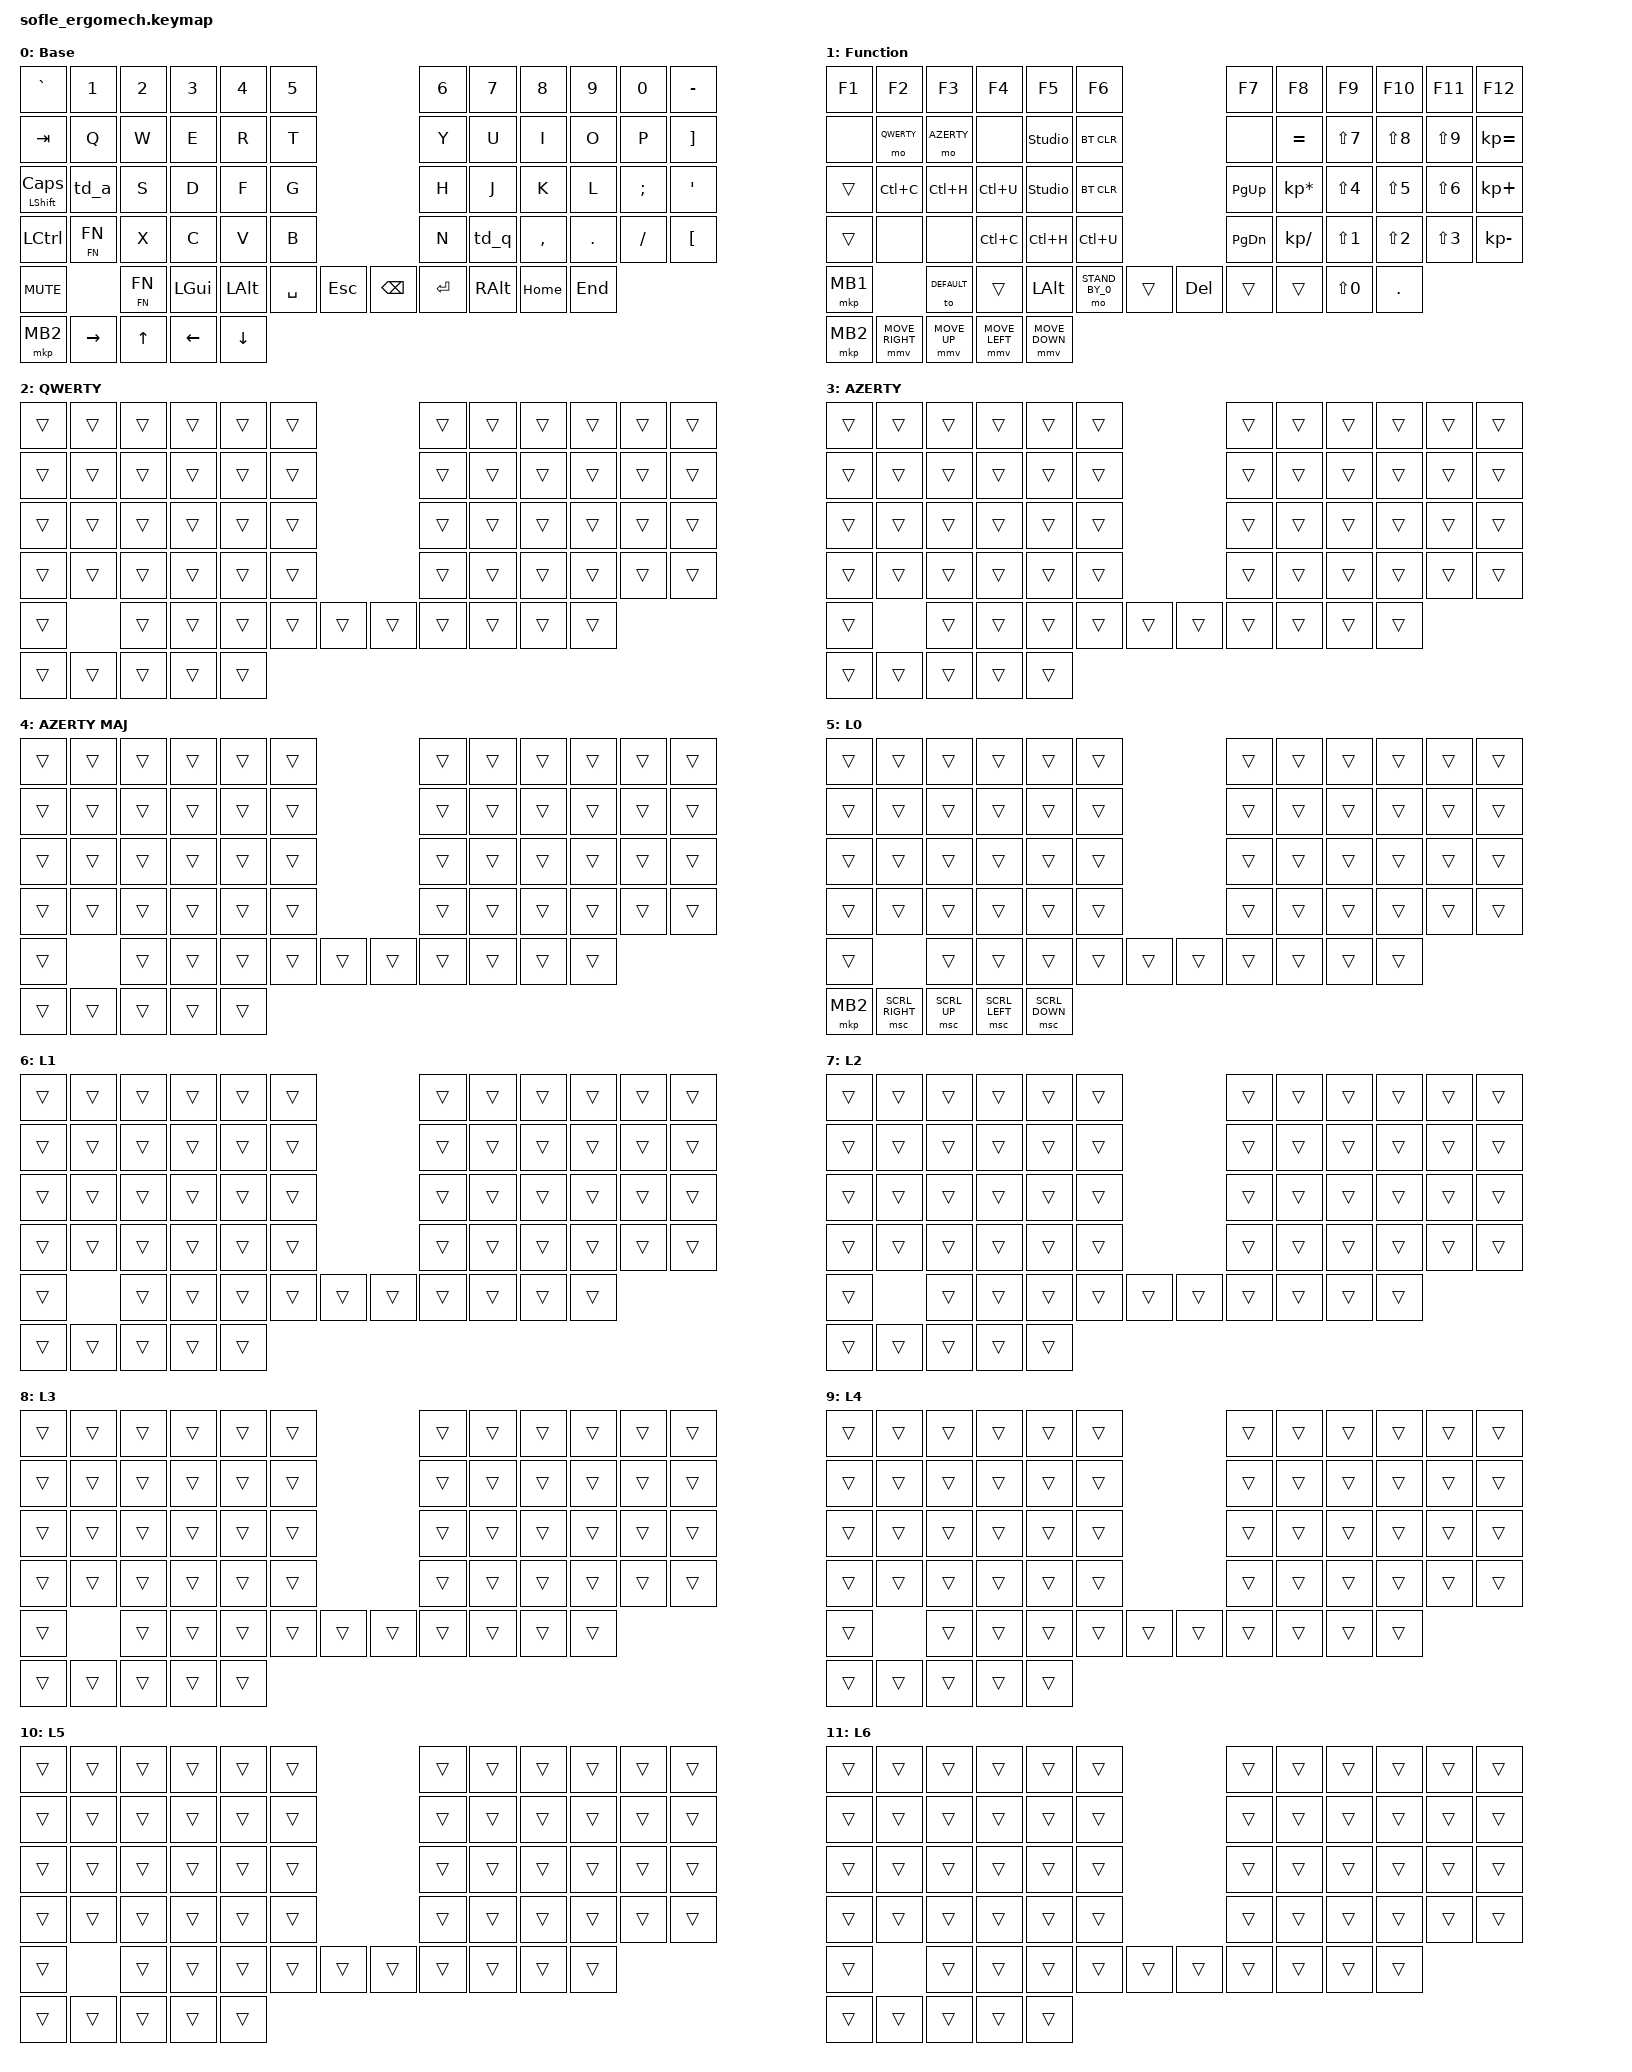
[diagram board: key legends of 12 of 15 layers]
/*
 * Copyright (c) 2020 The ZMK Contributors
 *
 * SPDX-License-Identifier: MIT
 */

#define ZMK_POINTING_DEFAULT_SCRL_VAL 300

#include <behaviors.dtsi>
#include <behaviors/mouse_move.dtsi>
#include <dt-bindings/zmk/keys.h>
#include <dt-bindings/zmk/pointing.h>

#include <dt-bindings/zmk/backlight.h>
#include <dt-bindings/zmk/behaviors.h>
#include <dt-bindings/zmk/bt.h>
#include <dt-bindings/zmk/ext_power.h>
#include <dt-bindings/zmk/hid_usage.h>
#include <dt-bindings/zmk/hid_usage_pages.h>
#include <dt-bindings/zmk/input_transform.h>
#include <dt-bindings/zmk/keys.h>
#include <dt-bindings/zmk/matrix_transform.h>
#include <dt-bindings/zmk/modifiers.h>
#include <dt-bindings/zmk/outputs.h>
#include <dt-bindings/zmk/pointing.h>
#include <dt-bindings/zmk/reset.h>
#include <dt-bindings/zmk/rgb.h>


#define DEFAULT     0
#define FN          1
#define QWERTY      2
#define AZERTY      3
#define AZERTY_MAJ  4

#define STAND_BY_0  5
#define STAND_BY_1  6
#define STAND_BY_2  7
#define STAND_BY_3  8
#define STAND_BY_4  9
#define STAND_BY_5  10
#define STAND_BY_6  11
#define STAND_BY_7  12
#define STAND_BY_8  13
#define STAND_BY_9  14

/ {
	behaviors {
		scrollup: scrollup {
			compatible = "zmk,behavior-macro";
            #binding-cells = <0>;
            bindings = <&msc SCRL_UP>, <&msc SCRL_UP>, <&msc SCRL_UP>, <&msc SCRL_UP>, <&msc SCRL_UP>, <&msc SCRL_UP>;
		};
		
		scrolldown: scrolldown {
			compatible = "zmk,behavior-macro";
            #binding-cells = <0>;
            bindings = <&msc SCRL_DOWN>, <&msc SCRL_DOWN>, <&msc SCRL_DOWN>, <&msc SCRL_DOWN>, <&msc SCRL_DOWN>, <&msc SCRL_DOWN>;
		};
		
		mousescroll: mousescroll {
            compatible = "zmk,behavior-sensor-rotate";
            #sensor-binding-cells = <0>;
            bindings = <&scrollup>, <&scrolldown>;
			tap-ms = <50>;
		};
		
		shift: hold_tap_shift {
			compatible = "zmk,behavior-hold-tap";
			#binding-cells = <2>;
			flavor = "hold-preferred";
			tapping-term-ms = <200>;
			bindings = <&kp>, <&kp>;
		};
		
		ht_l: hold_tap_layer {
			compatible = "zmk,behavior-hold-tap";
			#binding-cells = <2>;
			flavor = "hold-preferred";
			tapping-term-ms = <200>;
			bindings = <&mo>, <&to>;
		};
		
		td_q: td_q {
			compatible = "zmk,behavior-tap-dance";
			#binding-cells = <0>;
			tapping-term-ms = <200>;
			bindings = <&kp M>, <&kp BSLH>;
		};
		
		td_a: td_a {
			compatible = "zmk,behavior-tap-dance";
			#binding-cells = <0>;
			tapping-term-ms = <200>;
			bindings = <&kp A>, <&kp Z>;
		};
		
		// JOYSTICK
		kp_right: kp_right {
			compatible = "zmk,behavior-mod-morph";
            #binding-cells = <0>;
            bindings = <&kp RIGHT>, <&kp END>;
            mods = <MOD_LALT>;
		};
		
		kp_up: kp_up {
			compatible = "zmk,behavior-mod-morph";
            #binding-cells = <0>;
            bindings = <&kp UP>, <&kp PAGE_UP>;
            mods = <MOD_LALT>;
		};
		
		kp_left: kp_left {
			compatible = "zmk,behavior-mod-morph";
            #binding-cells = <0>;
            bindings = <&kp LEFT>, <&kp HOME>;
            mods = <MOD_LALT>;
		};
		
		kp_down: kp_down {
			compatible = "zmk,behavior-mod-morph";
            #binding-cells = <0>;
            bindings = <&kp DOWN>, <&kp PAGE_DOWN>;
            mods = <MOD_LALT>;
		};
	};
	
    keymap {
		compatible = "zmk,keymap";
		default_layer {
			label = "Base";
// ── DEFAULT ─────────────────────────────────────────────────────────────────────────────────────────────────────────────────────────────────────────────────────────────────────────────────────────────────────────────────────────────────────────
			bindings = <
// ╭────────────────┬────────────────┬────────────────┬────────────────┬────────────────┬────────────────╮                                      ╭────────────────┬────────────────┬────────────────┬────────────────┬────────────────┬────────────────╮
// │ $              │ "              │ «              │ »              │ (              │ )              │                                      │ @              │ +              │ -              │ /              │ *              │ =              │
     &kp GRAVE        &kp N1           &kp N2           &kp N3           &kp N4           &kp N5                                                  &kp N6           &kp N7           &kp N8            &kp N9          &kp N0           &kp MINUS
// ├────────────────┼────────────────┼────────────────┼────────────────┼────────────────┼────────────────┤                                      ├────────────────┼────────────────┼────────────────┼────────────────┼────────────────┼────────────────┤
// │ TAB            │ b              │ é              │ p              │ o              │ è              │                                      │ ^              │ v              │ d              │ l              │ j              │ w              │
     &kp TAB          &kp Q            &kp W            &kp E            &kp R            &kp T                                                   &kp Y            &kp U            &kp I            &kp O            &kp P            &kp RBKT
// ├────────────────┼────────────────┼────────────────┼────────────────┼────────────────┼────────────────┤                                      ├────────────────┼────────────────┼────────────────┼────────────────┼────────────────┼────────────────┤
// │ MAJ            │ a              │ u              │ i              │ e              │ ,              │                                      │ c              │ t              │ s              │ r              │ n              │ m              │
    &shift LSHFT CLCK &td_a            &kp S            &kp D            &kp F            &kp G                                                   &kp H            &kp J            &kp K            &kp L            &kp SEMI         &kp SQT
// ├────────────────┼────────────────┼────────────────┼────────────────┼────────────────┼────────────────┤                                      ├────────────────┼────────────────┼────────────────┼────────────────┼────────────────┼────────────────┤
// │ CTRL           │ à              │ y              │ x              │ .              │ k              │                                      │ '              │ q/ç            │ g              │ h              │ f              │ z              │
     &kp LCTRL        &ht_l FN FN        &kp X            &kp C            &kp V            &kp B                                                   &kp N            &td_q            &kp COMMA        &kp DOT          &kp FSLH         &kp LBKT
// ╰────────────────┴────────────────┼────────────────┼────────────────┼────────────────┼────────────────┼────────────────╮    ╭────────────────┼────────────────┼────────────────┼────────────────┼────────────────┼────────────────┼────────────────╯
//                                   │ <FN>           │ WIN            │ ALT            │ SPACE          │ ESC            │    │ BKSPC          │ ENTER          │ ALTGR          │ HOME           │ END            │
     &kp C_MUTE                        &ht_l FN FN      &kp LGUI         &kp LALT         &kp SPACE        &kp ESC               &kp BSPC         &kp ENTER        &kp RALT         &kp HOME         &kp END
//                                   ╰────────────────┴────────────────┴────────────────┴────────────────┴────────────────╯    ╰────────────────┴────────────────┴────────────────┴────────────────┴────────────────╯
&mkp MB2 &kp RIGHT &kp UP &kp LEFT &kp DOWN
			>;
			sensor-bindings = <&mousescroll &inc_dec_kp PG_UP PG_DN>;
		};
		
		fn_layer {
			label = "Function";
// ── FN ──────────────────────────────────────────────────────────────────────────────────────────────────────────────────────────────────────────────────────────────────────────────────────────────────────────────────────────────────────────────
			bindings = <
// ╭────────────────┬────────────────┬────────────────┬────────────────┬────────────────┬────────────────╮                                      ╭────────────────┬────────────────┬────────────────┬────────────────┬────────────────┬────────────────╮
// │ F1             │ F2             │ F3             │ F4             │ F5             │ F6             │                                      │ F7             │ F8             │ F9             │ F10            │ F11            │ F12            │
     &kp F1           &kp F2           &kp F3           &kp F4           &kp F5           &kp F6                                                  &kp F7           &kp F8           &kp F9           &kp F10          &kp F11          &kp F12
// ├────────────────┼────────────────┼────────────────┼────────────────┼────────────────┼────────────────┤                                      ├────────────────┼────────────────┼────────────────┼────────────────┼────────────────┼────────────────┤
// │ studio         │ QWERTY         │ AZERTY         │                │                │                │                                      │                │ %              │ 7              │ 8              │ 9              │ =              │
     &none            &mo QWERTY       &mo AZERTY       &none            &studio_unlock   &bt BT_CLR                                              &none            &kp EQUAL        &kp LS(N7)       &kp LS(N8)       &kp LS(N9)       &kp KP_EQUAL
// ├────────────────┼────────────────┼────────────────┼────────────────┼────────────────┼────────────────┤                                      ├────────────────┼────────────────┼────────────────┼────────────────┼────────────────┼────────────────┤
// │ studio         │ CUT            │ COPY           │ PASTE          │                │                │                                      │ PAGE_UP        │ *              │ 4              │ 5              │ 6              │ +              │
     &trans           &kp LC(C)        &kp LC(H)        &kp LC(U)        &studio_unlock   &bt BT_CLR                                              &kp PAGE_UP      &kp KP_MULTIPLY  &kp LS(N4)       &kp LS(N5)       &kp LS(N6)       &kp KP_PLUS
// ├────────────────┼────────────────┼────────────────┼────────────────┼────────────────┼────────────────┤                                      ├────────────────┼────────────────┼────────────────┼────────────────┼────────────────┼────────────────┤
// │ BLUETOOTH      │                │                │ CUT            │ COPY           │ PASTE          │                                      │ PAGE_DOWN      │ /              │ 1              │ 2              │ 3              │ -              │
     &trans           &none            &none            &kp LC(C)        &kp LC(H)        &kp LC(U)                                               &kp PAGE_DOWN    &kp KP_SLASH     &kp LS(N1)       &kp LS(N2)       &kp LS(N3)       &kp KP_MINUS
// ╰────────────────┴────────────────┼────────────────┼────────────────┼────────────────┼────────────────┼────────────────╮    ╭────────────────┼────────────────┼────────────────┼────────────────┼────────────────┼────────────────┼────────────────╯
//                                   │ <FN>           │ WIN            │ ALT            │ STAND_BY_1     │ ESC            │    │ BKSPC          │ ENTER          │ ALTGR          │ 0              │ .              │
     &mkp MB1                          &to DEFAULT      &trans           &kp LALT         &mo STAND_BY_0   &trans                &kp DELETE       &trans           &trans           &kp LS(N0)       &kp DOT
//                                   ╰────────────────┴────────────────┴────────────────┴────────────────┴────────────────╯    ╰────────────────┴────────────────┴────────────────┴────────────────┴────────────────╯
&mkp MB2 &mmv MOVE_RIGHT &mmv MOVE_UP &mmv MOVE_LEFT &mmv MOVE_DOWN
			>;
			sensor-bindings = <&inc_dec_kp C_VOL_UP C_VOL_DN &inc_dec_kp PG_UP PG_DN>;
		};
		
		qwerty_layer {
			label = "QWERTY";
// ── QWERTY ──────────────────────────────────────────────────────────────────────────────────────────────────────────────────────────────────────────────────────────────────────────────────────────────────────────────────────────────────────────
			bindings = <
// ╭────────────────┬────────────────┬────────────────┬────────────────┬────────────────┬────────────────╮                                      ╭────────────────┬────────────────┬────────────────┬────────────────┬────────────────┬────────────────╮
// │                │                │                │                │                │                │                                      │                │                │                │                │                │                │
     &trans           &trans           &trans           &trans           &trans           &trans                                                  &trans           &trans           &trans           &trans           &trans           &trans
// ├────────────────┼────────────────┼────────────────┼────────────────┼────────────────┼────────────────┤                                      ├────────────────┼────────────────┼────────────────┼────────────────┼────────────────┼────────────────┤
// │                │                │                │                │                │                │                                      │                │                │                │                │                │                │
     &trans           &trans           &trans           &trans           &trans           &trans                                                  &trans           &trans           &trans           &trans           &trans           &trans
// ├────────────────┼────────────────┼────────────────┼────────────────┼────────────────┼────────────────┤                                      ├────────────────┼────────────────┼────────────────┼────────────────┼────────────────┼────────────────┤
// │                │                │                │                │                │                │                                      │                │                │                │                │                │                │
     &trans           &trans           &trans           &trans           &trans           &trans                                                  &trans           &trans           &trans           &trans           &trans           &trans
// ├────────────────┼────────────────┼────────────────┼────────────────┼────────────────┼────────────────┤                                      ├────────────────┼────────────────┼────────────────┼────────────────┼────────────────┼────────────────┤
// │                │                │                │                │                │                │                                      │                │                │                │                │                │                │
     &trans           &trans           &trans           &trans           &trans           &trans                                                  &trans           &trans           &trans           &trans           &trans           &trans
// ╰────────────────┴────────────────┼────────────────┼────────────────┼────────────────┼────────────────┼────────────────╮    ╭────────────────┼────────────────┼────────────────┼────────────────┼────────────────┼────────────────┼────────────────╯
//                                   │                │                │                │                │                │    │                │                │                │                │                │
     &trans                            &trans           &trans           &trans           &trans           &trans                &trans           &trans           &trans           &trans           &trans
//                                   ╰────────────────┴────────────────┴────────────────┴────────────────┴────────────────╯    ╰────────────────┴────────────────┴────────────────┴────────────────┴────────────────╯
&trans &trans &trans &trans &trans
			>;
			sensor-bindings = <&inc_dec_kp C_VOL_UP C_VOL_DN &inc_dec_kp PG_UP PG_DN>;
		};
		
		azerty_layer {
			label = "AZERTY";
// ── AZERTY ──────────────────────────────────────────────────────────────────────────────────────────────────────────────────────────────────────────────────────────────────────────────────────────────────────────────────────────────────────────
			bindings = <
// ╭────────────────┬────────────────┬────────────────┬────────────────┬────────────────┬────────────────╮                                      ╭────────────────┬────────────────┬────────────────┬────────────────┬────────────────┬────────────────╮
// │                │                │                │                │                │                │                                      │                │                │                │                │                │                │
     &trans           &trans           &trans           &trans           &trans           &trans                                                  &trans           &trans           &trans           &trans           &trans           &trans
// ├────────────────┼────────────────┼────────────────┼────────────────┼────────────────┼────────────────┤                                      ├────────────────┼────────────────┼────────────────┼────────────────┼────────────────┼────────────────┤
// │                │                │                │                │                │                │                                      │                │                │                │                │                │                │
     &trans           &trans           &trans           &trans           &trans           &trans                                                  &trans           &trans           &trans           &trans           &trans           &trans
// ├────────────────┼────────────────┼────────────────┼────────────────┼────────────────┼────────────────┤                                      ├────────────────┼────────────────┼────────────────┼────────────────┼────────────────┼────────────────┤
// │                │                │                │                │                │                │                                      │                │                │                │                │                │                │
     &trans           &trans           &trans           &trans           &trans           &trans                                                  &trans           &trans           &trans           &trans           &trans           &trans
// ├────────────────┼────────────────┼────────────────┼────────────────┼────────────────┼────────────────┤                                      ├────────────────┼────────────────┼────────────────┼────────────────┼────────────────┼────────────────┤
// │                │                │                │                │                │                │                                      │                │                │                │                │                │                │
     &trans           &trans           &trans           &trans           &trans           &trans                                                  &trans           &trans           &trans           &trans           &trans           &trans
// ╰────────────────┴────────────────┼────────────────┼────────────────┼────────────────┼────────────────┼────────────────╮    ╭────────────────┼────────────────┼────────────────┼────────────────┼────────────────┼────────────────┼────────────────╯
//                                   │                │                │                │                │                │    │                │                │                │                │                │
     &trans                            &trans           &trans           &trans           &trans           &trans                &trans           &trans           &trans           &trans           &trans
//                                   ╰────────────────┴────────────────┴────────────────┴────────────────┴────────────────╯    ╰────────────────┴────────────────┴────────────────┴────────────────┴────────────────╯
&trans &trans &trans &trans &trans
			>;
			sensor-bindings = <&inc_dec_kp C_VOL_UP C_VOL_DN &inc_dec_kp PG_UP PG_DN>;
		};
		
		azertymaj_layer {
			label = "AZERTY MAJ";
// ── AZERTY ──────────────────────────────────────────────────────────────────────────────────────────────────────────────────────────────────────────────────────────────────────────────────────────────────────────────────────────────────────────
			bindings = <
// ╭────────────────┬────────────────┬────────────────┬────────────────┬────────────────┬────────────────╮                                      ╭────────────────┬────────────────┬────────────────┬────────────────┬────────────────┬────────────────╮
// │                │                │                │                │                │                │                                      │                │                │                │                │                │                │
     &trans           &trans           &trans           &trans           &trans           &trans                                                  &trans           &trans           &trans           &trans           &trans           &trans
// ├────────────────┼────────────────┼────────────────┼────────────────┼────────────────┼────────────────┤                                      ├────────────────┼────────────────┼────────────────┼────────────────┼────────────────┼────────────────┤
// │                │                │                │                │                │                │                                      │                │                │                │                │                │                │
     &trans           &trans           &trans           &trans           &trans           &trans                                                  &trans           &trans           &trans           &trans           &trans           &trans
// ├────────────────┼────────────────┼────────────────┼────────────────┼────────────────┼────────────────┤                                      ├────────────────┼────────────────┼────────────────┼────────────────┼────────────────┼────────────────┤
// │                │                │                │                │                │                │                                      │                │                │                │                │                │                │
     &trans           &trans           &trans           &trans           &trans           &trans                                                  &trans           &trans           &trans           &trans           &trans           &trans
// ├────────────────┼────────────────┼────────────────┼────────────────┼────────────────┼────────────────┤                                      ├────────────────┼────────────────┼────────────────┼────────────────┼────────────────┼────────────────┤
// │                │                │                │                │                │                │                                      │                │                │                │                │                │                │
     &trans           &trans           &trans           &trans           &trans           &trans                                                  &trans           &trans           &trans           &trans           &trans           &trans
// ╰────────────────┴────────────────┼────────────────┼────────────────┼────────────────┼────────────────┼────────────────╮    ╭────────────────┼────────────────┼────────────────┼────────────────┼────────────────┼────────────────┼────────────────╯
//                                   │                │                │                │                │                │    │                │                │                │                │                │
     &trans                            &trans           &trans           &trans           &trans           &trans                &trans           &trans           &trans           &trans           &trans
//                                   ╰────────────────┴────────────────┴────────────────┴────────────────┴────────────────╯    ╰────────────────┴────────────────┴────────────────┴────────────────┴────────────────╯
&trans &trans &trans &trans &trans
			>;
			sensor-bindings = <&inc_dec_kp C_VOL_UP C_VOL_DN &inc_dec_kp PG_UP PG_DN>;
		};
		
		standby0_layer {
			label = "L0";
// ── AZERTY ──────────────────────────────────────────────────────────────────────────────────────────────────────────────────────────────────────────────────────────────────────────────────────────────────────────────────────────────────────────
			bindings = <
// ╭────────────────┬────────────────┬────────────────┬────────────────┬────────────────┬────────────────╮                                      ╭────────────────┬────────────────┬────────────────┬────────────────┬────────────────┬────────────────╮
// │                │                │                │                │                │                │                                      │                │                │                │                │                │                │
     &trans           &trans           &trans           &trans           &trans           &trans                                                  &trans           &trans           &trans           &trans           &trans           &trans
// ├────────────────┼────────────────┼────────────────┼────────────────┼────────────────┼────────────────┤                                      ├────────────────┼────────────────┼────────────────┼────────────────┼────────────────┼────────────────┤
// │                │                │                │                │                │                │                                      │                │                │                │                │                │                │
     &trans           &trans           &trans           &trans           &trans           &trans                                                  &trans           &trans           &trans           &trans           &trans           &trans
// ├────────────────┼────────────────┼────────────────┼────────────────┼────────────────┼────────────────┤                                      ├────────────────┼────────────────┼────────────────┼────────────────┼────────────────┼────────────────┤
// │                │                │                │                │                │                │                                      │                │                │                │                │                │                │
     &trans           &trans           &trans           &trans           &trans           &trans                                                  &trans           &trans           &trans           &trans           &trans           &trans
// ├────────────────┼────────────────┼────────────────┼────────────────┼────────────────┼────────────────┤                                      ├────────────────┼────────────────┼────────────────┼────────────────┼────────────────┼────────────────┤
// │                │                │                │                │                │                │                                      │                │                │                │                │                │                │
     &trans           &trans           &trans           &trans           &trans           &trans                                                  &trans           &trans           &trans           &trans           &trans           &trans
// ╰────────────────┴────────────────┼────────────────┼────────────────┼────────────────┼────────────────┼────────────────╮    ╭────────────────┼────────────────┼────────────────┼────────────────┼────────────────┼────────────────┼────────────────╯
//                                   │                │                │                │                │                │    │                │                │                │                │                │
     &trans                            &trans           &trans           &trans           &trans           &trans                &trans           &trans           &trans           &trans           &trans
//                                   ╰────────────────┴────────────────┴────────────────┴────────────────┴────────────────╯    ╰────────────────┴────────────────┴────────────────┴────────────────┴────────────────╯
&mkp MB2 &msc SCRL_RIGHT &msc SCRL_UP &msc SCRL_LEFT &msc SCRL_DOWN
			>;
			sensor-bindings = <&inc_dec_kp C_VOL_UP C_VOL_DN &inc_dec_kp PG_UP PG_DN>;
		};
		
		standby1_layer {
			label = "L1";
// ── AZERTY ──────────────────────────────────────────────────────────────────────────────────────────────────────────────────────────────────────────────────────────────────────────────────────────────────────────────────────────────────────────
			bindings = <
// ╭────────────────┬────────────────┬────────────────┬────────────────┬────────────────┬────────────────╮                                      ╭────────────────┬────────────────┬────────────────┬────────────────┬────────────────┬────────────────╮
// │                │                │                │                │                │                │                                      │                │                │                │                │                │                │
     &trans           &trans           &trans           &trans           &trans           &trans                                                  &trans           &trans           &trans           &trans           &trans           &trans
// ├────────────────┼────────────────┼────────────────┼────────────────┼────────────────┼────────────────┤                                      ├────────────────┼────────────────┼────────────────┼────────────────┼────────────────┼────────────────┤
// │                │                │                │                │                │                │                                      │                │                │                │                │                │                │
     &trans           &trans           &trans           &trans           &trans           &trans                                                  &trans           &trans           &trans           &trans           &trans           &trans
// ├────────────────┼────────────────┼────────────────┼────────────────┼────────────────┼────────────────┤                                      ├────────────────┼────────────────┼────────────────┼────────────────┼────────────────┼────────────────┤
// │                │                │                │                │                │                │                                      │                │                │                │                │                │                │
     &trans           &trans           &trans           &trans           &trans           &trans                                                  &trans           &trans           &trans           &trans           &trans           &trans
// ├────────────────┼────────────────┼────────────────┼────────────────┼────────────────┼────────────────┤                                      ├────────────────┼────────────────┼────────────────┼────────────────┼────────────────┼────────────────┤
// │                │                │                │                │                │                │                                      │                │                │                │                │                │                │
     &trans           &trans           &trans           &trans           &trans           &trans                                                  &trans           &trans           &trans           &trans           &trans           &trans
// ╰────────────────┴────────────────┼────────────────┼────────────────┼────────────────┼────────────────┼────────────────╮    ╭────────────────┼────────────────┼────────────────┼────────────────┼────────────────┼────────────────┼────────────────╯
//                                   │                │                │                │                │                │    │                │                │                │                │                │
     &trans                            &trans           &trans           &trans           &trans           &trans                &trans           &trans           &trans           &trans           &trans
//                                   ╰────────────────┴────────────────┴────────────────┴────────────────┴────────────────╯    ╰────────────────┴────────────────┴────────────────┴────────────────┴────────────────╯
&trans &trans &trans &trans &trans
			>;
			sensor-bindings = <&inc_dec_kp C_VOL_UP C_VOL_DN &inc_dec_kp PG_UP PG_DN>;
		};
		
		standby2_layer {
			label = "L2";
// ── AZERTY ──────────────────────────────────────────────────────────────────────────────────────────────────────────────────────────────────────────────────────────────────────────────────────────────────────────────────────────────────────────
			bindings = <
// ╭────────────────┬────────────────┬────────────────┬────────────────┬────────────────┬────────────────╮                                      ╭────────────────┬────────────────┬────────────────┬────────────────┬────────────────┬────────────────╮
// │                │                │                │                │                │                │                                      │                │                │                │                │                │                │
     &trans           &trans           &trans           &trans           &trans           &trans                                                  &trans           &trans           &trans           &trans           &trans           &trans
// ├────────────────┼────────────────┼────────────────┼────────────────┼────────────────┼────────────────┤                                      ├────────────────┼────────────────┼────────────────┼────────────────┼────────────────┼────────────────┤
// │                │                │                │                │                │                │                                      │                │                │                │                │                │                │
     &trans           &trans           &trans           &trans           &trans           &trans                                                  &trans           &trans           &trans           &trans           &trans           &trans
// ├────────────────┼────────────────┼────────────────┼────────────────┼────────────────┼────────────────┤                                      ├────────────────┼────────────────┼────────────────┼────────────────┼────────────────┼────────────────┤
// │                │                │                │                │                │                │                                      │                │                │                │                │                │                │
     &trans           &trans           &trans           &trans           &trans           &trans                                                  &trans           &trans           &trans           &trans           &trans           &trans
// ├────────────────┼────────────────┼────────────────┼────────────────┼────────────────┼────────────────┤                                      ├────────────────┼────────────────┼────────────────┼────────────────┼────────────────┼────────────────┤
// │                │                │                │                │                │                │                                      │                │                │                │                │                │                │
     &trans           &trans           &trans           &trans           &trans           &trans                                                  &trans           &trans           &trans           &trans           &trans           &trans
// ╰────────────────┴────────────────┼────────────────┼────────────────┼────────────────┼────────────────┼────────────────╮    ╭────────────────┼────────────────┼────────────────┼────────────────┼────────────────┼────────────────┼────────────────╯
//                                   │                │                │                │                │                │    │                │                │                │                │                │
     &trans                            &trans           &trans           &trans           &trans           &trans                &trans           &trans           &trans           &trans           &trans
//                                   ╰────────────────┴────────────────┴────────────────┴────────────────┴────────────────╯    ╰────────────────┴────────────────┴────────────────┴────────────────┴────────────────╯
&trans &trans &trans &trans &trans
			>;
			sensor-bindings = <&inc_dec_kp C_VOL_UP C_VOL_DN &inc_dec_kp PG_UP PG_DN>;
		};
		
		standby3_layer {
			label = "L3";
// ── AZERTY ──────────────────────────────────────────────────────────────────────────────────────────────────────────────────────────────────────────────────────────────────────────────────────────────────────────────────────────────────────────
			bindings = <
// ╭────────────────┬────────────────┬────────────────┬────────────────┬────────────────┬────────────────╮                                      ╭────────────────┬────────────────┬────────────────┬────────────────┬────────────────┬────────────────╮
// │                │                │                │                │                │                │                                      │                │                │                │                │                │                │
     &trans           &trans           &trans           &trans           &trans           &trans                                                  &trans           &trans           &trans           &trans           &trans           &trans
// ├────────────────┼────────────────┼────────────────┼────────────────┼────────────────┼────────────────┤                                      ├────────────────┼────────────────┼────────────────┼────────────────┼────────────────┼────────────────┤
// │                │                │                │                │                │                │                                      │                │                │                │                │                │                │
     &trans           &trans           &trans           &trans           &trans           &trans                                                  &trans           &trans           &trans           &trans           &trans           &trans
// ├────────────────┼────────────────┼────────────────┼────────────────┼────────────────┼────────────────┤                                      ├────────────────┼────────────────┼────────────────┼────────────────┼────────────────┼────────────────┤
// │                │                │                │                │                │                │                                      │                │                │                │                │                │                │
     &trans           &trans           &trans           &trans           &trans           &trans                                                  &trans           &trans           &trans           &trans           &trans           &trans
// ├────────────────┼────────────────┼────────────────┼────────────────┼────────────────┼────────────────┤                                      ├────────────────┼────────────────┼────────────────┼────────────────┼────────────────┼────────────────┤
// │                │                │                │                │                │                │                                      │                │                │                │                │                │                │
     &trans           &trans           &trans           &trans           &trans           &trans                                                  &trans           &trans           &trans           &trans           &trans           &trans
// ╰────────────────┴────────────────┼────────────────┼────────────────┼────────────────┼────────────────┼────────────────╮    ╭────────────────┼────────────────┼────────────────┼────────────────┼────────────────┼────────────────┼────────────────╯
//                                   │                │                │                │                │                │    │                │                │                │                │                │
     &trans                            &trans           &trans           &trans           &trans           &trans                &trans           &trans           &trans           &trans           &trans
//                                   ╰────────────────┴────────────────┴────────────────┴────────────────┴────────────────╯    ╰────────────────┴────────────────┴────────────────┴────────────────┴────────────────╯
&trans &trans &trans &trans &trans
			>;
			sensor-bindings = <&inc_dec_kp C_VOL_UP C_VOL_DN &inc_dec_kp PG_UP PG_DN>;
		};
		
		standby4_layer {
			label = "L4";
// ── AZERTY ──────────────────────────────────────────────────────────────────────────────────────────────────────────────────────────────────────────────────────────────────────────────────────────────────────────────────────────────────────────
			bindings = <
// ╭────────────────┬────────────────┬────────────────┬────────────────┬────────────────┬────────────────╮                                      ╭────────────────┬────────────────┬────────────────┬────────────────┬────────────────┬────────────────╮
// │                │                │                │                │                │                │                                      │                │                │                │                │                │                │
     &trans           &trans           &trans           &trans           &trans           &trans                                                  &trans           &trans           &trans           &trans           &trans           &trans
// ├────────────────┼────────────────┼────────────────┼────────────────┼────────────────┼────────────────┤                                      ├────────────────┼────────────────┼────────────────┼────────────────┼────────────────┼────────────────┤
// │                │                │                │                │                │                │                                      │                │                │                │                │                │                │
     &trans           &trans           &trans           &trans           &trans           &trans                                                  &trans           &trans           &trans           &trans           &trans           &trans
// ├────────────────┼────────────────┼────────────────┼────────────────┼────────────────┼────────────────┤                                      ├────────────────┼────────────────┼────────────────┼────────────────┼────────────────┼────────────────┤
// │                │                │                │                │                │                │                                      │                │                │                │                │                │                │
     &trans           &trans           &trans           &trans           &trans           &trans                                                  &trans           &trans           &trans           &trans           &trans           &trans
// ├────────────────┼────────────────┼────────────────┼────────────────┼────────────────┼────────────────┤                                      ├────────────────┼────────────────┼────────────────┼────────────────┼────────────────┼────────────────┤
// │                │                │                │                │                │                │                                      │                │                │                │                │                │                │
     &trans           &trans           &trans           &trans           &trans           &trans                                                  &trans           &trans           &trans           &trans           &trans           &trans
// ╰────────────────┴────────────────┼────────────────┼────────────────┼────────────────┼────────────────┼────────────────╮    ╭────────────────┼────────────────┼────────────────┼────────────────┼────────────────┼────────────────┼────────────────╯
//                                   │                │                │                │                │                │    │                │                │                │                │                │
     &trans                            &trans           &trans           &trans           &trans           &trans                &trans           &trans           &trans           &trans           &trans
//                                   ╰────────────────┴────────────────┴────────────────┴────────────────┴────────────────╯    ╰────────────────┴────────────────┴────────────────┴────────────────┴────────────────╯
&trans &trans &trans &trans &trans
			>;
			sensor-bindings = <&inc_dec_kp C_VOL_UP C_VOL_DN &inc_dec_kp PG_UP PG_DN>;
		};
		
		standby5_layer {
			label = "L5";
// ── AZERTY ──────────────────────────────────────────────────────────────────────────────────────────────────────────────────────────────────────────────────────────────────────────────────────────────────────────────────────────────────────────
			bindings = <
// ╭────────────────┬────────────────┬────────────────┬────────────────┬────────────────┬────────────────╮                                      ╭────────────────┬────────────────┬────────────────┬────────────────┬────────────────┬────────────────╮
// │                │                │                │                │                │                │                                      │                │                │                │                │                │                │
     &trans           &trans           &trans           &trans           &trans           &trans                                                  &trans           &trans           &trans           &trans           &trans           &trans
// ├────────────────┼────────────────┼────────────────┼────────────────┼────────────────┼────────────────┤                                      ├────────────────┼────────────────┼────────────────┼────────────────┼────────────────┼────────────────┤
// │                │                │                │                │                │                │                                      │                │                │                │                │                │                │
     &trans           &trans           &trans           &trans           &trans           &trans                                                  &trans           &trans           &trans           &trans           &trans           &trans
// ├────────────────┼────────────────┼────────────────┼────────────────┼────────────────┼────────────────┤                                      ├────────────────┼────────────────┼────────────────┼────────────────┼────────────────┼────────────────┤
// │                │                │                │                │                │                │                                      │                │                │                │                │                │                │
     &trans           &trans           &trans           &trans           &trans           &trans                                                  &trans           &trans           &trans           &trans           &trans           &trans
// ├────────────────┼────────────────┼────────────────┼────────────────┼────────────────┼────────────────┤                                      ├────────────────┼────────────────┼────────────────┼────────────────┼────────────────┼────────────────┤
// │                │                │                │                │                │                │                                      │                │                │                │                │                │                │
     &trans           &trans           &trans           &trans           &trans           &trans                                                  &trans           &trans           &trans           &trans           &trans           &trans
// ╰────────────────┴────────────────┼────────────────┼────────────────┼────────────────┼────────────────┼────────────────╮    ╭────────────────┼────────────────┼────────────────┼────────────────┼────────────────┼────────────────┼────────────────╯
//                                   │                │                │                │                │                │    │                │                │                │                │                │
     &trans                            &trans           &trans           &trans           &trans           &trans                &trans           &trans           &trans           &trans           &trans
//                                   ╰────────────────┴────────────────┴────────────────┴────────────────┴────────────────╯    ╰────────────────┴────────────────┴────────────────┴────────────────┴────────────────╯
&trans &trans &trans &trans &trans
			>;
			sensor-bindings = <&inc_dec_kp C_VOL_UP C_VOL_DN &inc_dec_kp PG_UP PG_DN>;
		};
		
		standby6_layer {
			label = "L6";
// ── AZERTY ──────────────────────────────────────────────────────────────────────────────────────────────────────────────────────────────────────────────────────────────────────────────────────────────────────────────────────────────────────────
			bindings = <
// ╭────────────────┬────────────────┬────────────────┬────────────────┬────────────────┬────────────────╮                                      ╭────────────────┬────────────────┬────────────────┬────────────────┬────────────────┬────────────────╮
// │                │                │                │                │                │                │                                      │                │                │                │                │                │                │
     &trans           &trans           &trans           &trans           &trans           &trans                                                  &trans           &trans           &trans           &trans           &trans           &trans
// ├────────────────┼────────────────┼────────────────┼────────────────┼────────────────┼────────────────┤                                      ├────────────────┼────────────────┼────────────────┼────────────────┼────────────────┼────────────────┤
// │                │                │                │                │                │                │                                      │                │                │                │                │                │                │
     &trans           &trans           &trans           &trans           &trans           &trans                                                  &trans           &trans           &trans           &trans           &trans           &trans
// ├────────────────┼────────────────┼────────────────┼────────────────┼────────────────┼────────────────┤                                      ├────────────────┼────────────────┼────────────────┼────────────────┼────────────────┼────────────────┤
// │                │                │                │                │                │                │                                      │                │                │                │                │                │                │
     &trans           &trans           &trans           &trans           &trans           &trans                                                  &trans           &trans           &trans           &trans           &trans           &trans
// ├────────────────┼────────────────┼────────────────┼────────────────┼────────────────┼────────────────┤                                      ├────────────────┼────────────────┼────────────────┼────────────────┼────────────────┼────────────────┤
// │                │                │                │                │                │                │                                      │                │                │                │                │                │                │
     &trans           &trans           &trans           &trans           &trans           &trans                                                  &trans           &trans           &trans           &trans           &trans           &trans
// ╰────────────────┴────────────────┼────────────────┼────────────────┼────────────────┼────────────────┼────────────────╮    ╭────────────────┼────────────────┼────────────────┼────────────────┼────────────────┼────────────────┼────────────────╯
//                                   │                │                │                │                │                │    │                │                │                │                │                │
     &trans                            &trans           &trans           &trans           &trans           &trans                &trans           &trans           &trans           &trans           &trans
//                                   ╰────────────────┴────────────────┴────────────────┴────────────────┴────────────────╯    ╰────────────────┴────────────────┴────────────────┴────────────────┴────────────────╯
&trans &trans &trans &trans &trans
			>;
			sensor-bindings = <&inc_dec_kp C_VOL_UP C_VOL_DN &inc_dec_kp PG_UP PG_DN>;
		};
		
		standby7_layer {
			label = "L7";
// ── AZERTY ──────────────────────────────────────────────────────────────────────────────────────────────────────────────────────────────────────────────────────────────────────────────────────────────────────────────────────────────────────────
			bindings = <
// ╭────────────────┬────────────────┬────────────────┬────────────────┬────────────────┬────────────────╮                                      ╭────────────────┬────────────────┬────────────────┬────────────────┬────────────────┬────────────────╮
// │                │                │                │                │                │                │                                      │                │                │                │                │                │                │
     &trans           &trans           &trans           &trans           &trans           &trans                                                  &trans           &trans           &trans           &trans           &trans           &trans
// ├────────────────┼────────────────┼────────────────┼────────────────┼────────────────┼────────────────┤                                      ├────────────────┼────────────────┼────────────────┼────────────────┼────────────────┼────────────────┤
// │                │                │                │                │                │                │                                      │                │                │                │                │                │                │
     &trans           &trans           &trans           &trans           &trans           &trans                                                  &trans           &trans           &trans           &trans           &trans           &trans
// ├────────────────┼────────────────┼────────────────┼────────────────┼────────────────┼────────────────┤                                      ├────────────────┼────────────────┼────────────────┼────────────────┼────────────────┼────────────────┤
// │                │                │                │                │                │                │                                      │                │                │                │                │                │                │
     &trans           &trans           &trans           &trans           &trans           &trans                                                  &trans           &trans           &trans           &trans           &trans           &trans
// ├────────────────┼────────────────┼────────────────┼────────────────┼────────────────┼────────────────┤                                      ├────────────────┼────────────────┼────────────────┼────────────────┼────────────────┼────────────────┤
// │                │                │                │                │                │                │                                      │                │                │                │                │                │                │
     &trans           &trans           &trans           &trans           &trans           &trans                                                  &trans           &trans           &trans           &trans           &trans           &trans
// ╰────────────────┴────────────────┼────────────────┼────────────────┼────────────────┼────────────────┼────────────────╮    ╭────────────────┼────────────────┼────────────────┼────────────────┼────────────────┼────────────────┼────────────────╯
//                                   │                │                │                │                │                │    │                │                │                │                │                │
     &trans                            &trans           &trans           &trans           &trans           &trans                &trans           &trans           &trans           &trans           &trans
//                                   ╰────────────────┴────────────────┴────────────────┴────────────────┴────────────────╯    ╰────────────────┴────────────────┴────────────────┴────────────────┴────────────────╯
&trans &trans &trans &trans &trans
			>;
			sensor-bindings = <&inc_dec_kp C_VOL_UP C_VOL_DN &inc_dec_kp PG_UP PG_DN>;
		};
		
		standby8_layer {
			label = "L8";
// ── AZERTY ──────────────────────────────────────────────────────────────────────────────────────────────────────────────────────────────────────────────────────────────────────────────────────────────────────────────────────────────────────────
			bindings = <
// ╭────────────────┬────────────────┬────────────────┬────────────────┬────────────────┬────────────────╮                                      ╭────────────────┬────────────────┬────────────────┬────────────────┬────────────────┬────────────────╮
// │                │                │                │                │                │                │                                      │                │                │                │                │                │                │
     &trans           &trans           &trans           &trans           &trans           &trans                                                  &trans           &trans           &trans           &trans           &trans           &trans
// ├────────────────┼────────────────┼────────────────┼────────────────┼────────────────┼────────────────┤                                      ├────────────────┼────────────────┼────────────────┼────────────────┼────────────────┼────────────────┤
// │                │                │                │                │                │                │                                      │                │                │                │                │                │                │
     &trans           &trans           &trans           &trans           &trans           &trans                                                  &trans           &trans           &trans           &trans           &trans           &trans
// ├────────────────┼────────────────┼────────────────┼────────────────┼────────────────┼────────────────┤                                      ├────────────────┼────────────────┼────────────────┼────────────────┼────────────────┼────────────────┤
// │                │                │                │                │                │                │                                      │                │                │                │                │                │                │
     &trans           &trans           &trans           &trans           &trans           &trans                                                  &trans           &trans           &trans           &trans           &trans           &trans
// ├────────────────┼────────────────┼────────────────┼────────────────┼────────────────┼────────────────┤                                      ├────────────────┼────────────────┼────────────────┼────────────────┼────────────────┼────────────────┤
// │                │                │                │                │                │                │                                      │                │                │                │                │                │                │
     &trans           &trans           &trans           &trans           &trans           &trans                                                  &trans           &trans           &trans           &trans           &trans           &trans
// ╰────────────────┴────────────────┼────────────────┼────────────────┼────────────────┼────────────────┼────────────────╮    ╭────────────────┼────────────────┼────────────────┼────────────────┼────────────────┼────────────────┼────────────────╯
//                                   │                │                │                │                │                │    │                │                │                │                │                │
     &trans                            &trans           &trans           &trans           &trans           &trans                &trans           &trans           &trans           &trans           &trans
//                                   ╰────────────────┴────────────────┴────────────────┴────────────────┴────────────────╯    ╰────────────────┴────────────────┴────────────────┴────────────────┴────────────────╯
&trans &trans &trans &trans &trans
			>;
			sensor-bindings = <&inc_dec_kp C_VOL_UP C_VOL_DN &inc_dec_kp PG_UP PG_DN>;
		};
		
		standby9_layer {
			label = "L9";
// ── AZERTY ──────────────────────────────────────────────────────────────────────────────────────────────────────────────────────────────────────────────────────────────────────────────────────────────────────────────────────────────────────────
			bindings = <
// ╭────────────────┬────────────────┬────────────────┬────────────────┬────────────────┬────────────────╮                                      ╭────────────────┬────────────────┬────────────────┬────────────────┬────────────────┬────────────────╮
// │                │                │                │                │                │                │                                      │                │                │                │                │                │                │
     &trans           &trans           &trans           &trans           &trans           &trans                                                  &trans           &trans           &trans           &trans           &trans           &trans
// ├────────────────┼────────────────┼────────────────┼────────────────┼────────────────┼────────────────┤                                      ├────────────────┼────────────────┼────────────────┼────────────────┼────────────────┼────────────────┤
// │                │                │                │                │                │                │                                      │                │                │                │                │                │                │
     &trans           &trans           &trans           &trans           &trans           &trans                                                  &trans           &trans           &trans           &trans           &trans           &trans
// ├────────────────┼────────────────┼────────────────┼────────────────┼────────────────┼────────────────┤                                      ├────────────────┼────────────────┼────────────────┼────────────────┼────────────────┼────────────────┤
// │                │                │                │                │                │                │                                      │                │                │                │                │                │                │
     &trans           &trans           &trans           &trans           &trans           &trans                                                  &trans           &trans           &trans           &trans           &trans           &trans
// ├────────────────┼────────────────┼────────────────┼────────────────┼────────────────┼────────────────┤                                      ├────────────────┼────────────────┼────────────────┼────────────────┼────────────────┼────────────────┤
// │                │                │                │                │                │                │                                      │                │                │                │                │                │                │
     &trans           &trans           &trans           &trans           &trans           &trans                                                  &trans           &trans           &trans           &trans           &trans           &trans
// ╰────────────────┴────────────────┼────────────────┼────────────────┼────────────────┼────────────────┼────────────────╮    ╭────────────────┼────────────────┼────────────────┼────────────────┼────────────────┼────────────────┼────────────────╯
//                                   │                │                │                │                │                │    │                │                │                │                │                │
     &trans                            &trans           &trans           &trans           &trans           &trans                &trans           &trans           &trans           &trans           &trans
//                                   ╰────────────────┴────────────────┴────────────────┴────────────────┴────────────────╯    ╰────────────────┴────────────────┴────────────────┴────────────────┴────────────────╯
&trans &trans &trans &trans &trans
			>;
			sensor-bindings = <&inc_dec_kp C_VOL_UP C_VOL_DN &inc_dec_kp PG_UP PG_DN>;
		};
	};
};
